# ipro7 register map
Vendor: intelpro; Series: BTBLE
CPU: ipro7, little endian
Registers are 32-bit, read-write, reset 0x0 unless marked. A register's access mark holds for its fields unless they carry their own. Offsets are from the block's base; [hi:lo] are bit positions; {n}, {i} and the like mark numbered series.

## I2S
Base 0x30017000
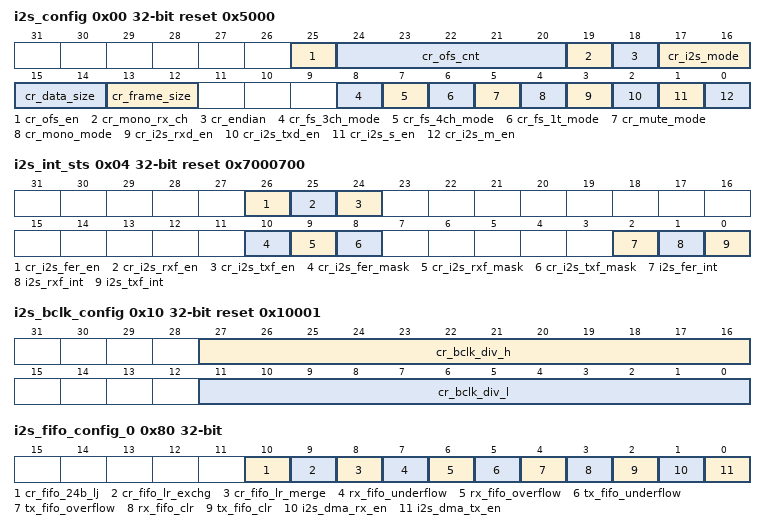
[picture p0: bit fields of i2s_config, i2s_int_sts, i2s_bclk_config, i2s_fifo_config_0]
0x00 i2s_config reset 0x5000
  [25] cr_ofs_en — Offset enable 1'b0: Disabled, 1'b1: Enabled
  [24:20] cr_ofs_cnt — Offset cycle count (unit: cycle of I2S BCLK) 5'd0: 1 cycle 5'd1: 2 cycles …
  [19] cr_mono_rx_ch — RX mono mode channel select signal 1'b0: L-channel 1'b1: R-channel
  [18] cr_endian — Data endian (bit reverse) 1'b0: MSB goes out first, 1'b1: LSB goes out first
  [17:16] cr_i2s_mode — 2'd0: Left-Justified, 2'd1: Right-Justified, 2'd2: DSP, 2'd3: Reserved
  [15:14] cr_data_size — Data bit width of each channel 2'd0: 8, 2'd1: 16, 2'd2: 24, 2'd3: 32 (bits)
  [13:12] cr_frame_size — Frame size of each channel 2'd0: 8, 2'd1: 16, 2'd2: 24, 2'd3: 32 (cycles)
  [8] cr_fs_3ch_mode — 1'b0: FS 2-channel mode, 1'b1: FS 3-channel mode (DSP mode only) Note: cr_fs_3ch_mode & cr_fs_4ch_mode should NOT be enabled at the same time Note: cr_mono_mode & cr_fifo_lr_merge will be invalid in 3-channel mode Note: When 3-channel mode is enabled, frame_size must equal data_size
  [7] cr_fs_4ch_mode — 1'b0: FS 2-channel mode, 1'b1: FS 4-channel mode (DSP mode only) Note: cr_fs_3ch_mode & cr_fs_4ch_mode should NOT be enabled at the same time Note: When 4-channel mode is enabled, frame_size must equal data_size
  [6] cr_fs_1t_mode — 1'b0: FS high/low is even, 1'b1: FS only asserts for 1 cycle
  [5] cr_mute_mode — 1'b0: Normal mode, 1'b1: Mute mode
  [4] cr_mono_mode — 1'b0: Stereo mode, 1'b1: Mono mode Note: csr_mono_mode & csr_fifo_lr_merge should NOT be enabled at the same time
  [3] cr_i2s_rxd_en — Enable signal of I2S RXD signal
  [2] cr_i2s_txd_en — Enable signal of I2S TXD signal
  [1] cr_i2s_s_en — Enable signal of I2S Slave function, cannot enable both csr_i2s_m_en & csr_i2s_s_en
  [0] cr_i2s_m_en — Enable signal of I2S Master function, cannot enable both csr_i2s_m_en & csr_i2s_s_en
0x04 i2s_int_sts reset 0x7000700 (reset mask 0xFFFFFFF8)
  [26] cr_i2s_fer_en — Interrupt enable of i2s_fer_int
  [25] cr_i2s_rxf_en — Interrupt enable of i2s_rxf_int
  [24] cr_i2s_txf_en — Interrupt enable of i2s_txf_int
  [10] cr_i2s_fer_mask — Interrupt mask of i2s_fer_int
  [9] cr_i2s_rxf_mask — Interrupt mask of i2s_rxf_int
  [8] cr_i2s_txf_mask — Interrupt mask of i2s_txf_int
  [2] i2s_fer_int ro — I2S TX/RX FIFO error interrupt, auto-cleared when FIFO overflow/underflow error flag is cleared
  [1] i2s_rxf_int ro — I2S RX FIFO ready (rx_fifo_cnt > rx_fifo_th) interrupt, auto-cleared when data is popped
  [0] i2s_txf_int ro — I2S TX FIFO ready (tx_fifo_cnt > tx_fifo_th) interrupt, auto-cleared when data is pushed
0x10 i2s_bclk_config reset 0x10001
  [27:16] cr_bclk_div_h — I2S BCLK active high period (unit: cycle of i2s_clk)
  [11:0] cr_bclk_div_l — I2S BCLK active low period (unit: cycle of i2s_clk)
0x80 i2s_fifo_config_0 (reset mask 0xFFFFFF0F)
  [10] cr_fifo_24b_lj — FIFO 24-bit data left-justified mode 1'b0: Right-justified, {8'h0, data[23:0]} 1'b1: Left-justified, {data[23:0], 8'h0} Note: Valid only when cr_data_size = 2'd2 (24-bit)
  [9] cr_fifo_lr_exchg — The position of L/R channel data within each entry is exchanged if this bit is enabled Can only be enabled if data size is 8 or 16 bits and csr_fifo_lr_merge is enabled
  [8] cr_fifo_lr_merge — Each FIFO entry contains both L/R channel data if this bit is enabled Can only be enabled if data size is 8 or 16 bits Note: cr_fifo_lr_merge &cr_mono_mode should NOT be enabled at the same time Note: cr_fifo_lr_merge &cr_fifo_l_shift should NOT be enabled at the same time
  [7] rx_fifo_underflow ro — Underflow flag of RX FIFO, can be cleared by rx_fifo_clr
  [6] rx_fifo_overflow ro — Overflow flag of RX FIFO, can be cleared by rx_fifo_clr
  [5] tx_fifo_underflow ro — Underflow flag of TX FIFO, can be cleared by tx_fifo_clr
  [4] tx_fifo_overflow ro — Overflow flag of TX FIFO, can be cleared by tx_fifo_clr
  [3] rx_fifo_clr — Clear signal of RX FIFO
  [2] tx_fifo_clr — Clear signal of TX FIFO
  [1] i2s_dma_rx_en — Enable signal of dma_rx_req/ack interface
  [0] i2s_dma_tx_en — Enable signal of dma_tx_req/ack interface
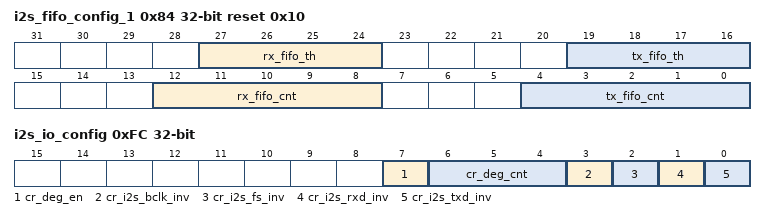
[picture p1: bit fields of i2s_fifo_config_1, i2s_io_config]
0x84 i2s_fifo_config_1 reset 0x10 (reset mask 0xFFFFE0E0)
  [27:24] rx_fifo_th — RX FIFO threshold, dma_rx_req will not be asserted if tx_fifo_cnt is less than this value
  [19:16] tx_fifo_th — TX FIFO threshold, dma_tx_req will not be asserted if tx_fifo_cnt is less than this value
  [12:8] rx_fifo_cnt ro — RX FIFO available count
  [4:0] tx_fifo_cnt ro — TX FIFO available count
0x88 i2s_fifo_wdata
  [31:0] i2s_fifo_wdata wo
0x8C i2s_fifo_rdata reset not defined
  [31:0] i2s_fifo_rdata ro
0xFC i2s_io_config
  [7] cr_deg_en — Deglitch enable (for all th input pins) 1'b0: Disabled, 1'b1: Enabled
  [6:4] cr_deg_cnt — Deglitch cycle count (unit: cycle of I2S kernel clock) 3'd0: 1 cycle 3'd1: 2 cycles …
  [3] cr_i2s_bclk_inv — Inverse BCLK signal 0: No inverse, 1: Inverse
  [2] cr_i2s_fs_inv — Inverse FS signal 0: No inverse, 1: Inverse
  [1] cr_i2s_rxd_inv — Inverse RXD signal 0: No inverse, 1: Inverse
  [0] cr_i2s_txd_inv — Inverse TXD signal 0: No inverse, 1: Inverse
